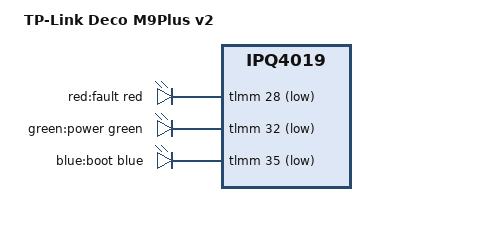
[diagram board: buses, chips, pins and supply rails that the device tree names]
// SPDX-License-Identifier: ISC
// Copyright (c) 2015, The Linux Foundation. All rights reserved.
// Copyright (c) 2021, Frank Veltmans <veltmans.frank@gmail.com>
#include "qcom-ipq4019-deco-m9plus-v2.dtsi"
/ {
	model = "TP-Link Deco M9Plus v2";
	compatible = "tplink,deco-m9plus-v2";
	leds {
		compatible = "gpio-leds";
		led_red: led-0 {
			label = "red:fault";
			gpios = <&tlmm 28 GPIO_ACTIVE_LOW>;
			color = <LED_COLOR_ID_RED>;
			function = LED_FUNCTION_FAULT;
		};
		led_green: led-1 {
			label = "green:power";
			gpios = <&tlmm 32 GPIO_ACTIVE_LOW>;
			color = <LED_COLOR_ID_GREEN>;
			function = LED_FUNCTION_POWER;
		};
		led_blue: led-2 {
			label = "blue:boot";
			gpios = <&tlmm 35 GPIO_ACTIVE_LOW>;
			color = <LED_COLOR_ID_BLUE>;
			function = LED_FUNCTION_BOOT;
		};
	};
};
